AUTOSAR XML (schema 4-2-2)
package /Components
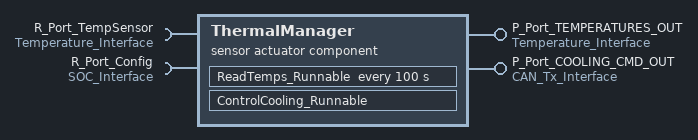
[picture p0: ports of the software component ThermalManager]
  sensor actuator sw component type ThermalManager
    provide port P_Port_TEMPERATURES_OUT: provided-interface=Temperature_Interface
    provide port P_Port_COOLING_CMD_OUT: provided-interface=CAN_Tx_Interface
    require port R_Port_TempSensor: required-interface=Temperature_Interface
    require port R_Port_Config: required-interface=SOC_Interface
    behavior ThermalManager_Behavior
      data received event Actuator_Status_Received: start-on-event=ControlCooling_Runnable
      timing event Temp_Period_100ms: start-on-event=ReadTemps_Runnable, period=100
      runnable ReadTemps_Runnable: minimum-start-interval=100, symbol=ThermalManager_ReadTemps
        data-read-access:
          access Read_Config: accessed-variable=R_Port_Config.confidence
        data-receive-point-by-values:
          access Receive_Temps: accessed-variable=R_Port_TempSensor.temperatures
        data-send-points:
          access Send_Temperatures_Out: accessed-variable=P_Port_TEMPERATURES_OUT.temperatures
        data-write-access:
          access Write_NoOp_CoolingCmd: accessed-variable=P_Port_COOLING_CMD_OUT.CAN_Frame
      runnable ControlCooling_Runnable: minimum-start-interval=20, symbol=ThermalManager_ControlCooling
        data-read-access:
          access Read_Latest_Temps: accessed-variable=P_Port_TEMPERATURES_OUT.temperatures
        data-receive-point-by-values:
          access Receive_Actuator_Status: accessed-variable=R_Port_Config.SOC
        data-send-points:
          access Send_Cooling_Command: accessed-variable=P_Port_COOLING_CMD_OUT.CAN_Frame
        data-write-access:
          access Write_Cooling_Command: accessed-variable=P_Port_COOLING_CMD_OUT.CAN_Frame
